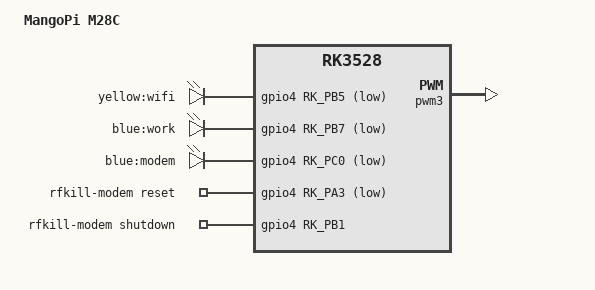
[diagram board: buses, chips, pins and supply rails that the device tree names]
// SPDX-License-Identifier: (GPL-2.0+ OR MIT)
// Copyright (c) 2025 AY <amadeus@jmu.edu.cn>

/dts-v1/;

#include "rk3528-mangopi-m28.dtsi"

/ {
	model = "MangoPi M28C";
	compatible = "widora,mangopi-m28c", "rockchip,rk3528";

	aliases {
		led-boot = &led_work;
		led-failsafe = &led_work;
		led-running = &led_work;
		led-upgrade = &led_work;
	};

	leds {
		compatible = "gpio-leds";
		pinctrl-names = "default";
		pinctrl-0 = <&lan_led_en>, <&wan_led_en>, <&work_led_en>;

		wifi {
			label = "yellow:wifi";
			gpios = <&gpio4 RK_PB5 GPIO_ACTIVE_LOW>;
		};

		led_work: work {
			label = "blue:work";
			gpios = <&gpio4 RK_PB7 GPIO_ACTIVE_LOW>;
		};

		modem {
			label = "blue:modem";
			gpios = <&gpio4 RK_PC0 GPIO_ACTIVE_LOW>;
		};
	};

	rfkill-modem {
		compatible = "rfkill-gpio";
		label = "rfkill-modem";
		radio-type = "wwan";
		reset-gpios = <&gpio4 RK_PA3 GPIO_ACTIVE_LOW>;
		shutdown-gpios = <&gpio4 RK_PB1 GPIO_ACTIVE_HIGH>;
	};
};

&pwm3 {
	status = "okay";
};

&sdhci {
	status = "disabled";
};

/* New version also changes vmmc-supply to vcc_3v3,
 * but needs to be compatible with old hardware. */
&sdmmc {
	max-frequency = <50000000>;
	/delete-property/ sd-uhs-sdr104;
	vqmmc-supply = <&vcc_3v3>;
};

&vccio_sd {
	status = "disabled";
};
